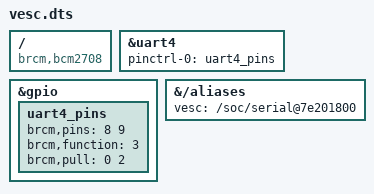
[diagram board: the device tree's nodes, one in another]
/dts-v1/;
/plugin/;

/ {
	compatible = "brcm,bcm2708";

	fragment@0 {
		target= <&uart4>;
		__overlay__ {
			pinctrl-names = "default";
			pinctrl-0 = <&uart4_pins>;
			status="okay";
		};
	};

	fragment@1 {
    		target = <&gpio>;
		__overlay__ {
      			uart4_pins: uart4_pins {
        			brcm,pins = <8 9>; /* UART4: TX4 RX4 */
        			brcm,function = <3>;    /* 2=ALT5, 3=ALT4, 7=ALT3, see https://www.kernel.org/doc/Documentation/devicetree/bindings/pinctrl/brcm,bcm2835-gpio.txt */
        			brcm,pull = <0 2>;
      			};
    		};
  	};

	fragment@2 {
    		target-path = "/aliases";
    		__overlay__ {
      			vesc = "/soc/serial@7e201800";
    		};
  	};
};
